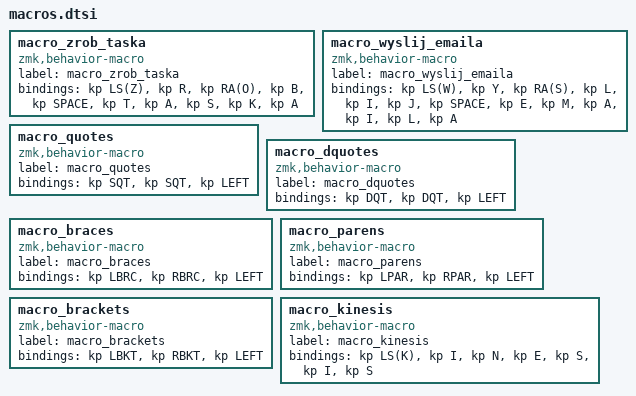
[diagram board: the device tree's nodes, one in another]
macro_zrob_taska: macro_zrob_taska{
compatible = "zmk,behavior-macro";
label = "macro_zrob_taska";
#binding-cells = <0>;
bindings = <&kp LS(Z)>, <&kp R>, <&kp RA(O)>, <&kp B>, <&kp SPACE>, <&kp T>, <&kp A>, <&kp S>, <&kp K>, <&kp A>;
};
macro_wyslij_emaila: macro_wyslij_emaila{
compatible = "zmk,behavior-macro";
label = "macro_wyslij_emaila";
#binding-cells = <0>;
bindings = <&kp LS(W)>, <&kp Y>, <&kp RA(S)>, <&kp L>, <&kp I>, <&kp J>, <&kp SPACE>, <&kp E>, <&kp M>, <&kp A>, <&kp I>, <&kp L>, <&kp A>;
};
macro_quotes: macro_quotes{
compatible = "zmk,behavior-macro";
label = "macro_quotes";
#binding-cells = <0>;
bindings = <&kp SQT>, <&kp SQT>, <&kp LEFT>;
};
macro_dquotes: macro_dquotes{
compatible = "zmk,behavior-macro";
label = "macro_dquotes";
#binding-cells = <0>;
bindings = <&kp DQT>, <&kp DQT>, <&kp LEFT>;
};
macro_braces: macro_braces{
compatible = "zmk,behavior-macro";
label = "macro_braces";
#binding-cells = <0>;
bindings = <&kp LBRC>, <&kp RBRC>, <&kp LEFT>;
};
macro_parens: macro_parens{
compatible = "zmk,behavior-macro";
label = "macro_parens";
#binding-cells = <0>;
bindings = <&kp LPAR>, <&kp RPAR>, <&kp LEFT>;
};
macro_brackets: macro_brackets{
compatible = "zmk,behavior-macro";
label = "macro_brackets";
#binding-cells = <0>;
bindings = <&kp LBKT>, <&kp RBKT>, <&kp LEFT>;
};
macro_kinesis: macro_kinesis{
compatible = "zmk,behavior-macro";
label = "macro_kinesis";
#binding-cells = <0>;
bindings = <&kp LS(K)>, <&kp I>, <&kp N>, <&kp E>, <&kp S>, <&kp I>, <&kp S>;
};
